# STM32L496AEI6 register map
File version: 1.0
Registers are 32-bit, access not given, reset 0x0 unless marked. A register's access mark holds for its fields unless they carry their own. Offsets are from the block's base; [hi:lo] are bit positions; {n}, {i} and the like mark numbered series; 'fields as' and 'values as' point back to an identical list.

## DCMI
Base 0x50050000
0x00 CR
  [20] OELS, [19] LSM, [18] OEBS, [17:16] BSM, [14] ENABLE, [31:12] s, [11:10] EDM, [9:8] FCRC, [7] VSPOL, [6] HSPOL, [5] PCKPOL, [4] ESS, [3] JPEG, [2] CROP, [1] CM, [0] CAPTURE
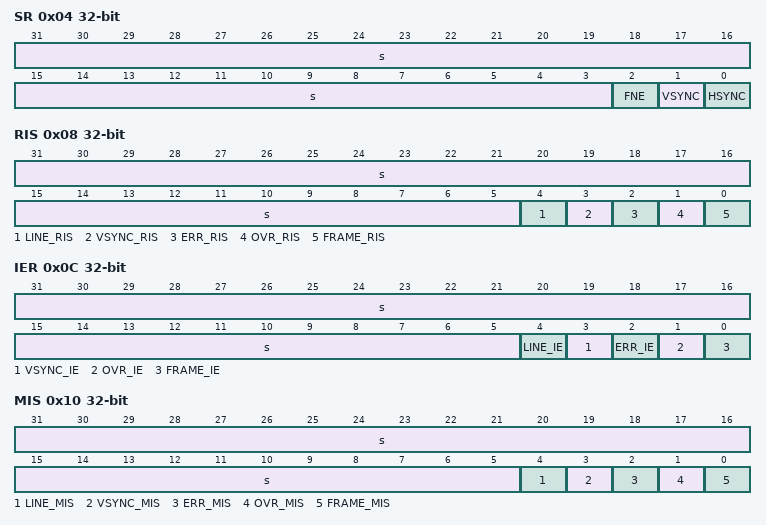
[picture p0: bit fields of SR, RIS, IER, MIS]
0x04 SR
  [31:3] s, [2] FNE, [1] VSYNC, [0] HSYNC
0x08 RIS
  [31:5] s, [4] LINE_RIS, [3] VSYNC_RIS, [2] ERR_RIS, [1] OVR_RIS, [0] FRAME_RIS
0x0C IER
  [31:5] s, [4] LINE_IE, [3] VSYNC_IE, [2] ERR_IE, [1] OVR_IE, [0] FRAME_IE
0x10 MIS
  [31:5] s, [4] LINE_MIS, [3] VSYNC_MIS, [2] ERR_MIS, [1] OVR_MIS, [0] FRAME_MIS
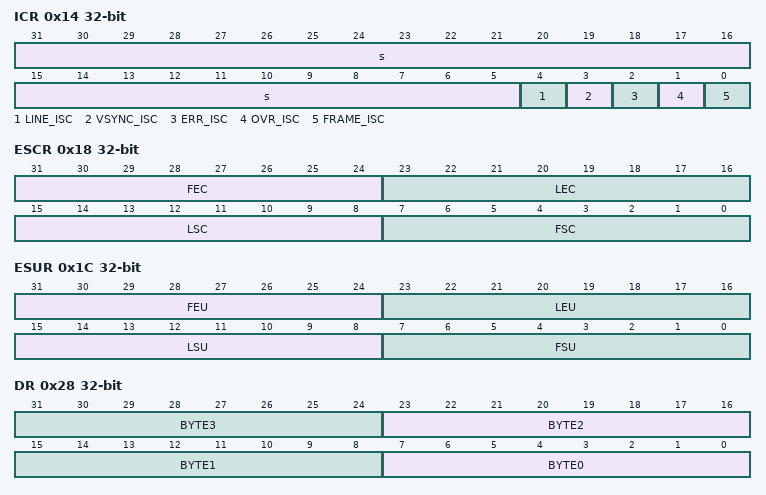
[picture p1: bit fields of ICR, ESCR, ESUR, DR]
0x14 ICR
  [31:5] s, [4] LINE_ISC, [3] VSYNC_ISC, [2] ERR_ISC, [1] OVR_ISC, [0] FRAME_ISC
0x18 ESCR
  [31:24] FEC, [23:16] LEC, [15:8] LSC, [7:0] FSC
0x1C ESUR
  [31:24] FEU, [23:16] LEU, [15:8] LSU, [7:0] FSU
0x20 CWSTRT
  [28:16] VST, [31:14] s, [13:0] HOFFCNT
0x24 CWSIZE
  [29:16] VLINE, [31:14] s, [13:0] CAPCNT
0x28 DR
  [8n+7:8n] BYTE{n} (n=0..3)

## AES
Base 0x50060000
0x00 CR
  [18] KEYSIZE, [31:15] s, [14:13] GCMPH, [12] DMAOUTEN, [11] DMAINEN, [10] ERRIE, [9] CCFIE, [8] ERRC, [7] CCFC, [16:5] CHMOD, [4:3] MODE, [2:1] DATATYPE, [0] EN
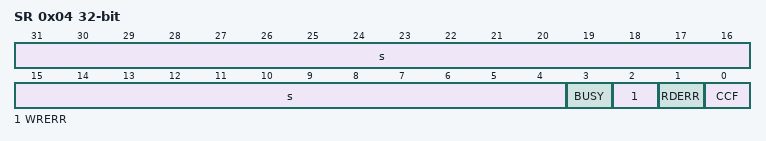
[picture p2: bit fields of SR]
0x04 SR
  [31:4] s, [3] BUSY, [2] WRERR, [1] RDERR, [0] CCF
0x08 DINR
  [31:0] DIN
0x0C DOUTR
  [31:0] DOUT
{0x10+4i} KEYR{i} (i=0..3)
  [31:0] KEY
{0x20+4i} IVR{i} (i=0..3)
  [31:0] IVI
{0x20+4i} KEYR{i} (i=4..7)
  [31:0] KEY
{0x40+4i} SUSP{i}R (i=0..7)
  [31:0] SUSP{i}

## HASH
Base 0x50060400
0x00 CR
  [16] LKEY, [13] MDMAT, [12] DINNE, [11:8] NBW, [18:7] ALGO, [6] MODE, [5:4] DATATYPE, [3] DMAE, [2] INIT, [31:0] s
0x04 DIN
  [31:0] DATAIN
0x08 STR
  [8] DCAL, [31:5] s, [4:0] NBLW
{0xC+4i} HRA{i} (i=0..4)
  [31:0] H{i}
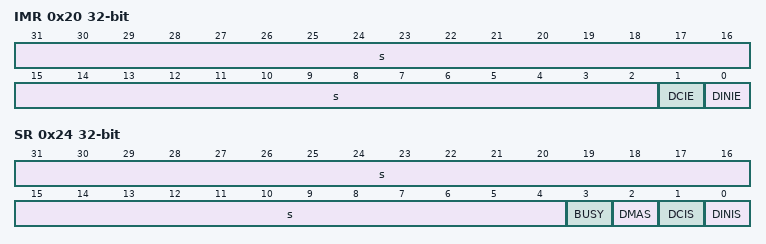
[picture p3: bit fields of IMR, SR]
0x20 IMR
  [31:2] s, [1] DCIE, [0] DINIE
0x24 SR
  [31:4] s, [3] BUSY, [2] DMAS, [1] DCIS, [0] DINIS
{0xFC+4i} CSR{i} (i=1..52)
  [31:0] CSx
{0x310+4i} HR{i} (i=0..7)
  [31:0] H{i}

## RNG
Base 0x50060800
0x00 CR
  [5] CED, [3] IE, [2] RNGEN, [31:0] s
0x04 SR
  [6] SEIS, [5] CEIS, [31:3] s, [2] SECS, [1] CECS, [0] DRDY
0x08 DR
  [31:0] RNDATA

## FMC
Base 0xA0000000
0x00 BCR1
  [21] WFDIS, [20] CCLKEN, [19] CBURSTRW, [18:16] CPSIZE, [15] ASYNCWAIT, [14] EXTMOD, [13] WAITEN, [12] WREN, [11] WAITCFG, [9] WAITPOL, [8] BURSTEN, [31:7] s, [6] FACCEN, [5:4] MWID, [3:2] MTYP, [1] MUXEN, [0] MBKEN
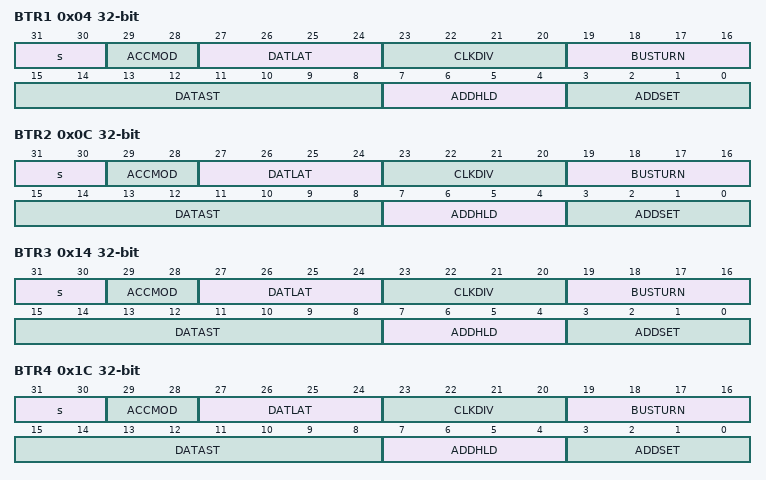
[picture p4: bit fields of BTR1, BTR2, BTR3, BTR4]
0x04 BTR1
  [31:30] s, [29:28] ACCMOD, [27:24] DATLAT, [23:20] CLKDIV, [19:16] BUSTURN, [15:8] DATAST, [7:4] ADDHLD, [3:0] ADDSET
0x08 BCR2
  [19] CBURSTRW, [18:16] CPSIZE, [15] ASYNCWAIT, [14] EXTMOD, [13] WAITEN, [12] WREN, [11] WAITCFG, [9] WAITPOL, [8] BURSTEN, [31:7] s, [6] FACCEN, [5:4] MWID, [3:2] MTYP, [1] MUXEN, [0] MBKEN
0x0C BTR2
  fields as BTR1
0x10 BCR3
  fields as BCR2
0x14 BTR3
  fields as BTR1
0x18 BCR4
  fields as BCR2
0x1C BTR4
  fields as BTR1
0x80 PCR
  [19:17] ECCPS, [16:13] TAR, [12:9] TCLR, [6] ECCEN, [5:4] PWID, [3] PTYP, [2] PBKEN, [1] PWAITEN, [31:0] s
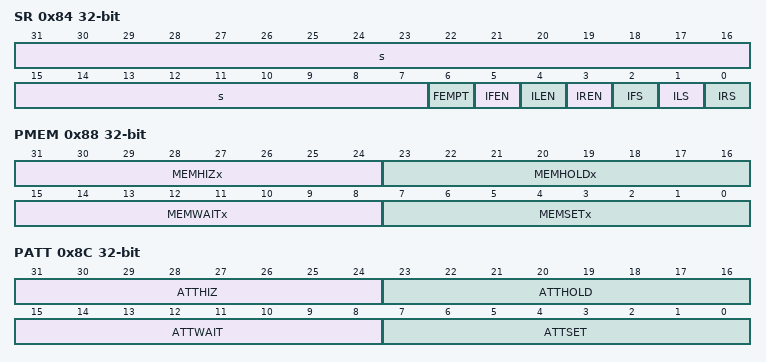
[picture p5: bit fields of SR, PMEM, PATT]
0x84 SR
  [31:7] s, [6] FEMPT, [5] IFEN, [4] ILEN, [3] IREN, [2] IFS, [1] ILS, [0] IRS
0x88 PMEM
  [31:24] MEMHIZx, [23:16] MEMHOLDx, [15:8] MEMWAITx, [7:0] MEMSETx
0x8C PATT
  [31:24] ATTHIZ, [23:16] ATTHOLD, [15:8] ATTWAIT, [7:0] ATTSET
0x94 ECCR
  [31:0] ECCx
{0xFC+8i} BWTR{i} (i=1..4)
  [29:28] ACCMOD, [31:20] s, [19:16] BUSTURN, [15:8] DATAST, [7:4] ADDHLD, [3:0] ADDSET

## QUADSPI
Base 0xA0001000
0x00 CR
  [31:24] PRESCALER, [23] PMM, [22] APMS, [20] TOIE, [19] SMIE, [18] FTIE, [17] TCIE, [16] TEIE, [11:8] FTHRES, [7] FSEL, [6] DFM, [21:5] s, [4] SSHIFT, [3] TCEN, [2] DMAEN, [1] ABORT, [0] EN
0x04 DCR
  [20:16] FSIZE, [10:8] CSHT, [31:1] s, [0] CKMODE
0x08 SR
  [12:8] FLEVEL, [31:6] s, [5] BUS, [4] TOF, [3] SMF, [2] FTF, [1] TCF, [0] TEF
0x0C FCR
  [4] CTOF, [3] CSMF, [31:2] s, [1] CTCF, [0] CTEF
0x10 DLR
  [31:0] DL
0x14 CCR
  [31] DDRM, [30] DHHC, [28] SIOO, [27:26] FMODE, [25:24] DMODE, [29:23] s, [22:18] DCYC, [17:16] ABSIZE, [15:14] ABMODE, [13:12] ADSIZE, [11:10] ADMODE, [9:8] IMODE, [7:0] INSTRUCTION
0x18 AR
  [31:0] ADDRESS
0x1C ABR
  [31:0] ALTERNATE
0x20 DR
  [31:0] DATA
0x24 PSMKR
  [31:0] MASK
0x28 PSMAR
  [31:0] MATCH
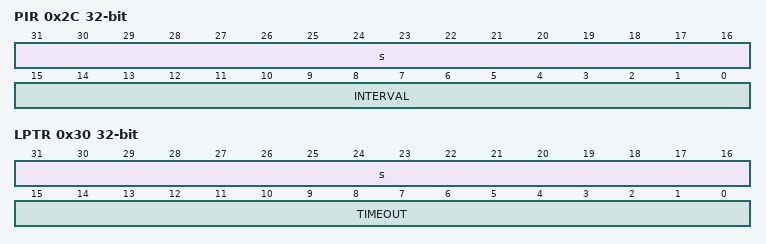
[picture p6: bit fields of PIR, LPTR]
0x2C PIR
  [31:16] s, [15:0] INTERVAL
0x30 LPTR
  [31:16] s, [15:0] TIMEOUT
